# TC37XPD register map
Vendor: Infineon; Series: ATVMC; File version: 100
CPU: other r0p0, little endian, MPU, FPU, vendor SysTick, 4 interrupt priority bits
Registers are 32-bit, read-write, reset 0x0 unless marked. A register's access mark holds for its fields unless they carry their own. Offsets are from the block's base; [hi:lo] are bit positions; {n}, {i} and the like mark numbered series; 'fields as' and 'values as' point back to an identical list.

## I2C0 — I2C
Base 0xF00C0000
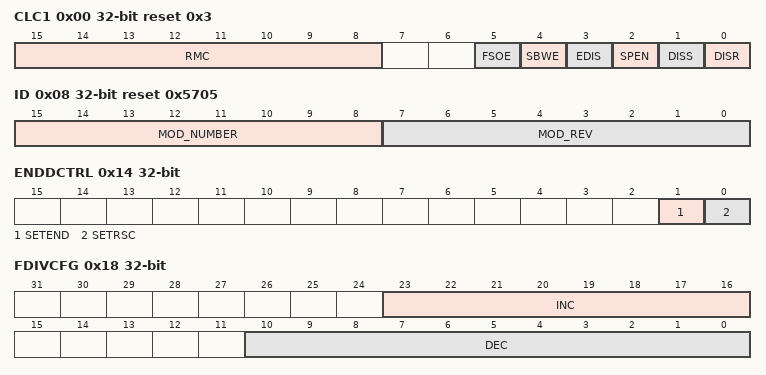
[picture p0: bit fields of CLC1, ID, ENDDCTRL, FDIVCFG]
0x00 CLC1 access per field reset 0x3 — Clock Control 1 Register resetvalue={Application Reset:0x3}
  [15:8] RMC rw — Clock Divider for Standard Run Mode RMC. Max. 8 bit divider value If RMC is set to 0 the module is disabled. As long as the new divider value RMC is not valid reading register returns 0000 00XX H
  [5] FSOE rw — Fast Switch Off Enable FSOE
  [4] SBWE wo — Module Suspend Bit Write Enable for OCDS SBWE. This bit is always read as 0.
  [3] EDIS rw — External Request Disable EDIS. This bit is not used in TC39x and should always be written with 0.
  [2] SPEN rw — Module Suspend Enable Bit for OCDS SPEN
  [1] DISS ro — Module Disable Status Bit DISS. Bit indicates the current status of the module.
  [0] DISR rw — Module Disable Request Bit DISR. Used for enable disable control of the module.
0x08 ID ro reset 0x5705 — Module Identification Register resetvalue={Application Reset:0x5705}
  [15:8] MOD_NUMBER — Module Number MOD NUMBER. This bit field defines the module identification number.
  [7:0] MOD_REV — Module Revision Number MOD REV. This bit field defines the revision number.
0x10 RUNCTRL — RUN Control Register resetvalue={Application Reset:0x0}
  [0] RUN — Enable I2C bus Interface RUN
0x14 ENDDCTRL wo — End Data Control Register resetvalue={Application Reset:0x0}
  [1] SETEND — Set End of Transmission SETEND. This bit is always read as 0. Do not write 1 to this bit when bus is free. This will cause an abort after the first byte when a new transfer is started. This 8217 command 8217 is buffered internally and gets valid after the next byte is transferred.
  [0] SETRSC — Set Restart Condition SETRSC. This bit is always read as 0.
0x18 FDIVCFG — Fractional Divider Configuration Register resetvalue={Application Reset:0x0}
  [23:16] INC — Increment Value of Fractional Divider INC. For standard fast mode see CROSSREFERENCE .
  [10:0] DEC — Decrement Value of Fractional Divider DEC. For standard fast mode see CROSSREFERENCE .
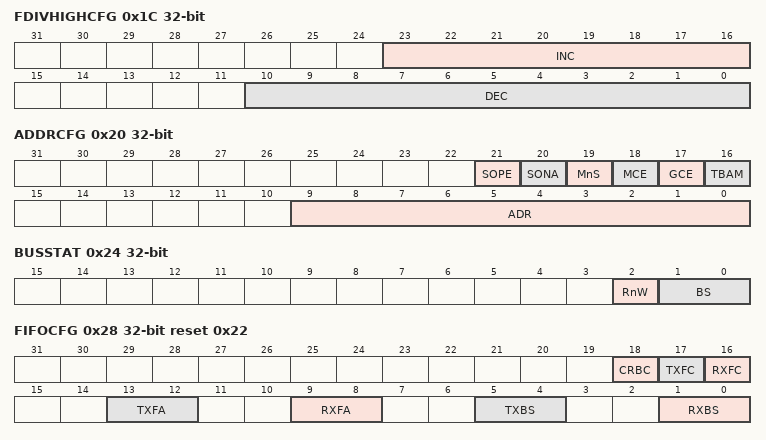
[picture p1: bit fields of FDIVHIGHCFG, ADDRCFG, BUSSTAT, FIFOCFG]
0x1C FDIVHIGHCFG — Fractional Divider High speed Mode Configuration Register resetvalue={Application Reset:0x0}
  [23:16] INC — Increment Value of Fractional Divider INC. For high speed mode see CROSSREFERENCE .
  [10:0] DEC — Decrement Value of Fractional Divider DEC. For high speed mode see CROSSREFERENCE .
0x20 ADDRCFG — Address Configuration Register resetvalue={Application Reset:0x0}
  [21] SOPE — Stop on Packet End SOPE. This bit field should be used only in Master Mode. In slave mode should always be 0. If device works as receiver a not acknowledge is always generated on package end. After successful transmission of a master code during high speed mode SOPE is not considered till a stop condition is manually generated by SETEND.
  [20] SONA — Stop on Not acknowledge SONA. After successful transmission of a master code during high speed mode SONA is not considered till a stop condition is manually generated by SETEND.
  [19] MnS — Master not Slave MnS
  [18] MCE — Master Code Enable MCE
  [17] GCE — General Call Enable GCE
  [16] TBAM — Ten Bit Address Mode TBAM. When this bit is zero only bits 7 down to 1 of the ADR field are valid.
  [9:0] ADR — I2C bus Device Address ADR. This bit field determines the address of the device when addressed as a slave. Watch out for reserved addresses by referring to I2C bus spec V2.1. Depending on setting of TBAM this is either a 7 bit address bits 7 1 or a 10 bit address bits 9 0 .
0x24 BUSSTAT ro — Bus Status Register resetvalue={Application Reset:0x0}
  [2] RnW — Read not Write RnW. Set by hardware automatically after address byte has been sent received.
  [1:0] BS — Bus Status BS. Shows the current status on the I2C bus.
0x28 FIFOCFG reset 0x22 — FIFO Configuration Register resetvalue={Application Reset:0x22}
  [18] CRBC — Clear Request Behavior Configuration CRBC. Used to configure the clear request behavior for the FIFO data request. Can only be used for single request and must be set to 8220 0 8221 when burst accesses are used in the system eg. when TX RXBS gt 0
  [17] TXFC — TX FIFO Flow Control TXFC
  [16] RXFC — RX FIFO Flow Control RXFC
  [13:12] TXFA — TX FIFO Alignment TXFA. Use byte alignment wherever it is possible.
  [9:8] RXFA — RX FIFO Alignment RXFA. Use byte alignment wherever it is possible.
  [5:4] TXBS — TX Burst Size TXBS. Some DMA controllers do not support a burst size of 2 words.
  [1:0] RXBS — RX Burst Size RXBS. Some DMA controllers do not support a burst size of 2 words.
0x2C MRPSCTRL — Maximum Received Packet Size Control Register resetvalue={Application Reset:0x0}
  [13:0] MRPS — Maximum Received Packet Size MRPS. Length in characters of packet to be received write value range 0 unlimited size to 16383 Reading returns the written value as long as the previous packet has not been read completely from the FIFO. After that MRPS is loaded to an internal register reading returns 0 and a new value can be written.
0x30 RPSSTAT ro — Received Packet Size Status Register resetvalue={Application Reset:0x0}
  [13:0] RPS — Received Packet Size RPS. Length in characters of the received packet 0 to 16383
0x34 TPSCTRL — Transmit Packet Size Control Register resetvalue={Application Reset:0x0}
  [13:0] TPS — Transmit Packet Size TPS. Length in characters of the transmit packet write value range 1 to 16383 Reading returns the written value as long as it is not loaded to an internal counter. After that reading returns 0 and a new value can be written.
0x38 FFSSTAT ro — Filled FIFO Stages Status Register resetvalue={Application Reset:0x0}
  [5:0] FFS — Filled FIFO Stages FFS. Number of filled FIFO stages 0 to 8
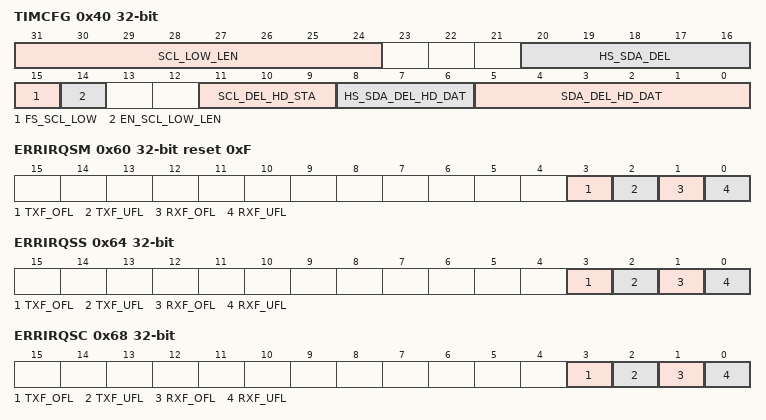
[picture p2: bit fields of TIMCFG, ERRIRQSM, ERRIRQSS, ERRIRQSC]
0x40 TIMCFG — Timing Configuration Register resetvalue={Application Reset:0x0}
  [31:24] SCL_LOW_LEN — SCL Low Length in Fast Mode SCL LOW LEN. If enabled by EN SCL LOW LEN setting this field determines the extension of the SCL low time. In case of INC 160 160 1 the low time is extended by the number of kernel clk cycles. In general there is a more complex formula as given in the functional specification. The total period time is not changed i.e. the SCL high period is reduced accordingly. Setting SCL low time to period length or higher is not supported and would lead to unpredictable results. 00
  [20:16] HS_SDA_DEL — SDA Delay Stages for Start Stop bit in High speed Mode HS SDA DEL
  [15] FS_SCL_LOW — Set Fast Mode SCL Low Period Timing FS SCL LOW. The internal duration of the SCL low time with respect to the period length as defined by the baudrate setting can be enlarged for the Fast Speed Mode in order to meet the asymmetric duty cycle requirements from the standard. The detailed formulas are given in the functional specification.
  [14] EN_SCL_LOW_LEN — Enable Direct Configuration of SCL Low Period Length in Fast Mode EN SCL LOW LEN
  [11:9] SCL_DEL_HD_STA — SCL Delay Stages for Hold Time Start Restart Bit SCL DEL HD STA
  [8:6] HS_SDA_DEL_HD_DAT — SDA Delay Stages for Data Hold Time in High speed Mode HS SDA DEL HD DAT. SDA delay stages for data hold time in HS mode. SDA delay from SCL falling edge but will also affect SDA Setup time relative to next SCL rising edge
  [5:0] SDA_DEL_HD_DAT — SDA Delay Stages for Data Hold Time in Standard and Fast modes SDA DEL HD DAT. SDA delay stages for data hold time in standard and fast modes. SDA delay from SCL falling edge but will also affect SDA Setup time relative to next SCL rising edge
0x60 ERRIRQSM reset 0xF — Error Interrupt Request Source Mask Register resetvalue={Application Reset:0x0F}
  [3] TXF_OFL — TX FIFO Overflow TXF OFL
  [2] TXF_UFL — TX FIFO Underflow TXF UFL
  [1] RXF_OFL — RX FIFO Overflow RXF OFL
  [0] RXF_UFL — RX FIFO Underflow RXF UFL
0x64 ERRIRQSS ro — Error Interrupt Request Source Status Register resetvalue={Application Reset:0x0}
  [3] TXF_OFL — TX FIFO Overflow TXF OFL. The FIFO has detected a TX FIFO overflow.
  [2] TXF_UFL — TX FIFO Underflow TXF UFL. The I2C kernel has detected a TX FIFO underflow.
  [1] RXF_OFL — RX FIFO Overflow RXF OFL. The I2C kernel has detected a RX FIFO overflow
  [0] RXF_UFL — RX FIFO Underflow RXF UFL. The FIFO has detected an RX FIFO underflow.
0x68 ERRIRQSC wo — Error Interrupt Request Source Clear Register resetvalue={Application Reset:0x0}
  fields as ERRIRQSM
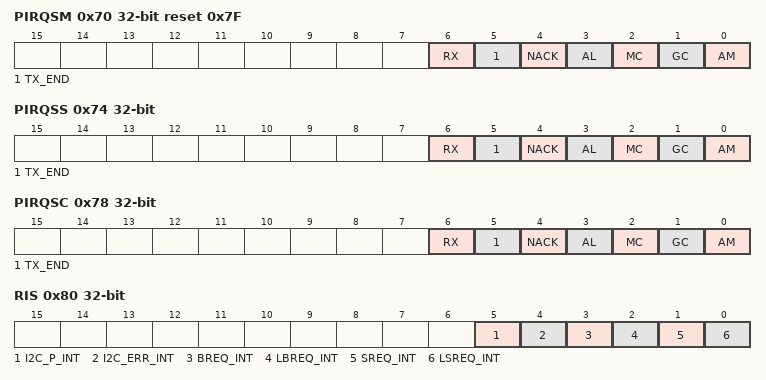
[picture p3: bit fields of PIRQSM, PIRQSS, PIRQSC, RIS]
0x70 PIRQSM reset 0x7F — Protocol Interrupt Request Source Mask Register resetvalue={Application Reset:0x7F}
  [6] RX — Receive Mode RX
  [5] TX_END — Transmission End TX END
  [4] NACK — Not acknowledge Received NACK
  [3] AL — Arbitration Lost AL
  [2] MC — Master Code MC
  [1] GC — General Call GC
  [0] AM — Address Match AM
0x74 PIRQSS ro — Protocol Interrupt Request Source Status Register resetvalue={Application Reset:0x0}
  [6] RX — Receive Mode RX. I2C kernel indicates switching from transmitting data to receiving data.
  [5] TX_END — Transmission End TX END. The device has ended the data transfer properly after stop condition has been put on the bus or the MASTER RESTART state has been entered.
  [4] NACK — Not acknowledge Received NACK. When working as transmitter this interrupt indicates a not acknowledge from the remote receiver. The SW has to decide what further steps have to be taken.
  [3] AL — Arbitration Lost AL. Device master mode lost the control on the I2C bus due to losing arbitration procedure. Accordingly bit field BS in register BUSSTAT is set to 01 .
  [2] MC — Master Code MC. Remote master has transmitted a master call.
  [1] GC — General Call GC. Remote master has transmitted a general call.
  [0] AM — Address Match AM. Device in master or slave mode is addressed by remote master matching device address . Accordingly bit field BS in register BUSSTAT is set to 11 .
0x78 PIRQSC wo — Protocol Interrupt Request Source Clear Register resetvalue={Application Reset:0x0}
  fields as PIRQSM
0x80 RIS ro — Raw Interrupt Status Register resetvalue={Application Reset:0x0}
  [5] I2C_P_INT — I2C Protocol Interrupt I2C P INT. This is the combined bit for indication of a protocol event in the I2C kernel.
  [4] I2C_ERR_INT — I2C Error Interrupt I2C ERR INT. This is the combined bit for indication of FIFO errors due to overflow and underflow.
  [3] BREQ_INT — Burst Request Interrupt BREQ INT
  [2] LBREQ_INT — Last Burst Request Interrupt LBREQ INT
  [1] SREQ_INT — Single Request Interrupt SREQ INT
  [0] LSREQ_INT — Last Single Request Interrupt LSREQ INT
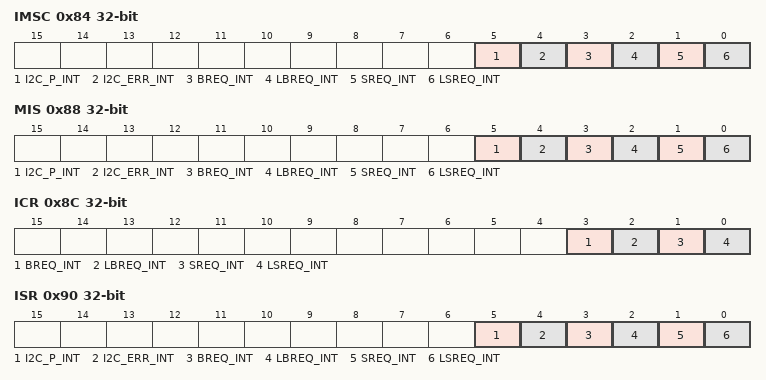
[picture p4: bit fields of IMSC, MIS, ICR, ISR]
0x84 IMSC — Interrupt Mask Control Register resetvalue={Application Reset:0x0}
  [5] I2C_P_INT — I2C Protocol Interrupt I2C P INT
  [4] I2C_ERR_INT — I2C Error Interrupt I2C ERR INT
  [3] BREQ_INT — Burst Request Interrupt BREQ INT
  [2] LBREQ_INT — Last Burst Request Interrupt LBREQ INT
  [1] SREQ_INT — Single Request Interrupt SREQ INT
  [0] LSREQ_INT — Last Single Request Interrupt LSREQ INT
0x88 MIS ro — Masked Interrupt Status Register resetvalue={Application Reset:0x0}
  fields as RIS
0x8C ICR wo — Interrupt Clear Register resetvalue={Application Reset:0x0}
  [3] BREQ_INT — Burst Request Interrupt BREQ INT
  [2] LBREQ_INT — Last Burst Request Interrupt LBREQ INT
  [1] SREQ_INT — Single Request Interrupt SREQ INT
  [0] LSREQ_INT — Last Single Request Interrupt LSREQ INT
0x90 ISR wo — Interrupt Set Register resetvalue={Application Reset:0x0}
  fields as IMSC
0x8000 TXD wo — Transmission Data Register resetvalue={Application Reset:0x0}
  [31:0] TXD — Transmission Data TXD. Characters to be transmitted
0xC000 RXD ro — Reception Data Register resetvalue={Application Reset:0x0}
  [31:0] RXD — Reception Data RXD. Received characters
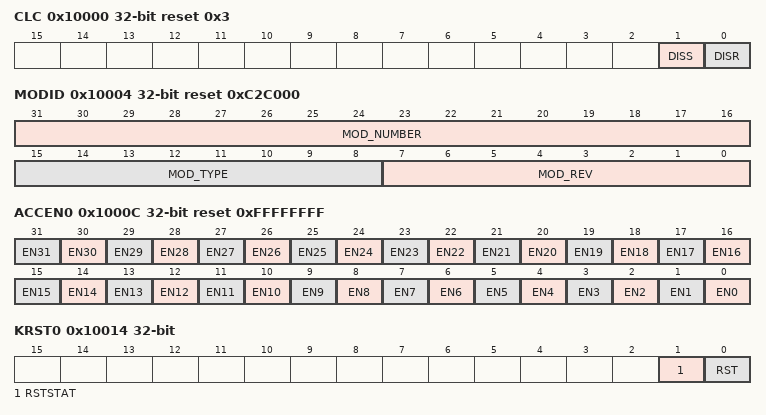
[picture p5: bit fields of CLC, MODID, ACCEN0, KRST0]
0x10000 CLC access per field reset 0x3 — Clock Control Register resetvalue={Application Reset:0x3}
  [1] DISS ro — Module Disable Status Bit DISS. Bit indicates the current status of the module.
  [0] DISR rw — Module Disable Request Bit DISR. Used for enable disable control of the module.
0x10004 MODID ro reset 0xC2C000 (reset mask 0xFFFFFF00) — Module Identification Register resetvalue={Application Reset:0x0C2C000}
  [31:16] MOD_NUMBER — Module Number Value MOD NUMBER. This bit field defines a module identification number.
  [15:8] MOD_TYPE — Module Type MOD TYPE. The bit field is set to C0H which defines the module as a 32 bit module.
  [7:0] MOD_REV — Module Revision Number MOD REV. This bit field defines the module revision number. The value of a module revision starts with 01H first revision .
0x10008 GPCTL — General Purpose Control Register resetvalue={Application Reset:0x0}
  [2:0] PISEL — Port Input Select PISEL. Used to select the input pins providing the serial data and clock input signals in the range of 0 to 7. In TC39x not all PISEL options are available. See Data Sheet.
0x1000C ACCEN0 reset 0xFFFFFFFF — Access Enable Register 0 resetvalue={Application Reset:0x0FFFFFFFF}
  [n] EN{n} (n=0..31) — Access Enable for Master TAG ID 31 EN31. This bit enables write access to the module register addresses for transactions with the Master TAG ID j
0x10014 KRST0 access per field — Kernel Reset Register 0 resetvalue={Application Reset:0x0}
  [1] RSTSTAT ro — Kernel Reset Status RSTSTAT. This bit indicates whether a kernel reset was executed or not. This bit is set after the execution of a kernel reset in the same clock cycle both reset bits. This bit can be cleared by writing with 1 to the CLR bit in the related KRSTCLR register.
  [0] RST rw — Kernel Reset RST. This reset bit can be used to request for a kernel reset. The kernel reset will be executed if the reset bits of both kernel registers are set. The RST bit will be cleared reset to 0 b after the kernel reset was executed.
0x10018 KRST1 — Kernel Reset Register 1 resetvalue={Application Reset:0x0}
  [0] RST — Kernel Reset RST. This reset bit can be used to request for a kernel reset. The kernel reset will be executed if the reset bits of both kernel reset registers is set. The RST bit will be cleared re set to 0 after the kernel reset was executed.
0x1001C KRSTCLR wo — Kernel Reset Status Clear Register resetvalue={Application Reset:0x0}
  [0] CLR — Kernel Reset Status Clear CLR. Read always as 0 .
